# BL702 register map
Vendor: Bouffalo Lab; Series: WiFi BT; File version: 1.0
Registers are 32-bit, read-write, reset 0x0 unless marked. A register's access mark holds for its fields unless they carry their own. Offsets are from the block's base; [hi:lo] are bit positions; {n}, {i} and the like mark numbered series.

## GLB — Global configuration register
Base 0x40000000
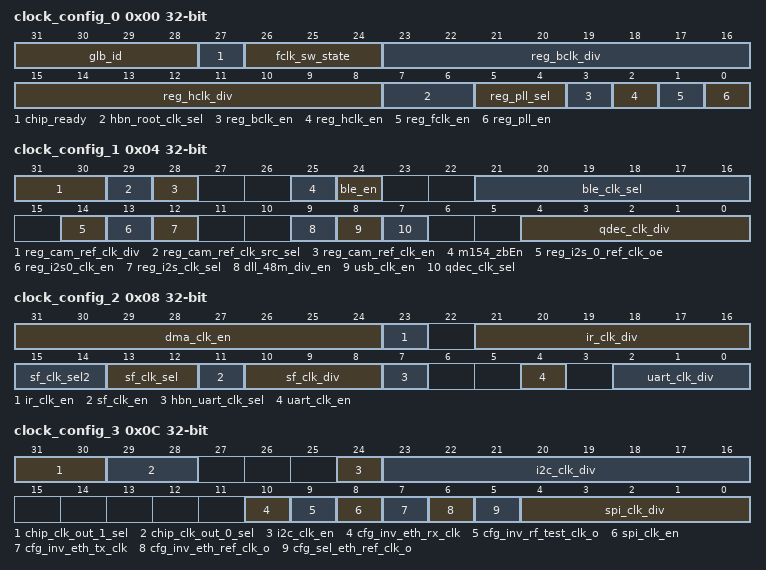
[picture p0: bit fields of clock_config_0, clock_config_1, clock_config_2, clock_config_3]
0x00 clock_config_0 — Clock configuration register 0
  [31:28] glb_id, [27] chip_ready, [26:24] fclk_sw_state, [23:16] reg_bclk_div, [15:8] reg_hclk_div, [7:6] hbn_root_clk_sel, [5:4] reg_pll_sel, [3] reg_bclk_en, [2] reg_hclk_en, [1] reg_fclk_en, [0] reg_pll_en
0x04 clock_config_1 — Clock configuration register 1
  [31:30] reg_cam_ref_clk_div, [29] reg_cam_ref_clk_src_sel, [28] reg_cam_ref_clk_en, [25] m154_zbEn, [24] ble_en, [21:16] ble_clk_sel, [14] reg_i2s_0_ref_clk_oe, [13] reg_i2s0_clk_en, [12] reg_i2s_clk_sel, [9] dll_48m_div_en, [8] usb_clk_en, [7] qdec_clk_sel, [4:0] qdec_clk_div
0x08 clock_config_2 — Clock configuration register 2
  [31:24] dma_clk_en, [23] ir_clk_en, [21:16] ir_clk_div, [15:14] sf_clk_sel2, [13:12] sf_clk_sel, [11] sf_clk_en, [10:8] sf_clk_div, [7] hbn_uart_clk_sel, [4] uart_clk_en, [2:0] uart_clk_div
0x0C clock_config_3 — Clock configuration register 3
  [31:30] chip_clk_out_1_sel, [29:28] chip_clk_out_0_sel, [24] i2c_clk_en, [23:16] i2c_clk_div, [10] cfg_inv_eth_rx_clk, [9] cfg_inv_rf_test_clk_o, [8] spi_clk_en, [7] cfg_inv_eth_tx_clk, [6] cfg_inv_eth_ref_clk_o, [5] cfg_sel_eth_ref_clk_o, [4:0] spi_clk_div
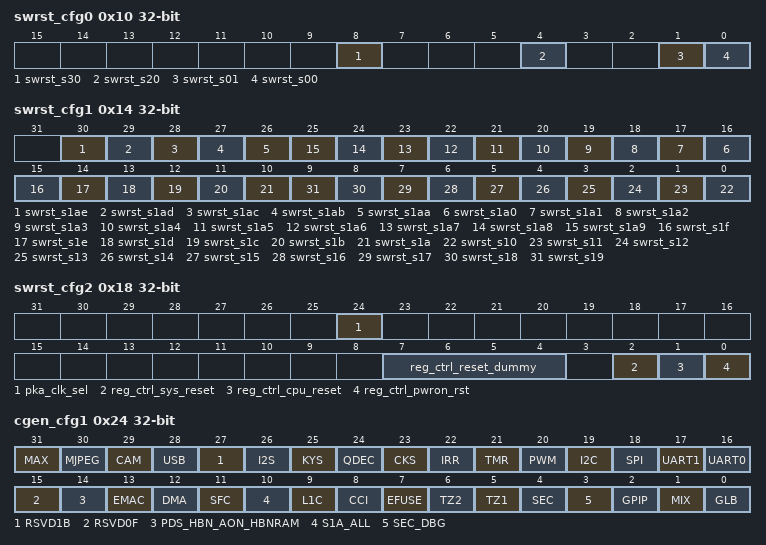
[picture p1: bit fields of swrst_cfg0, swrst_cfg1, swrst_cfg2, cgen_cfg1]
0x10 swrst_cfg0
  [8] swrst_s30, [4] swrst_s20, [1] swrst_s01, [0] swrst_s00
0x14 swrst_cfg1
  [30] swrst_s1ae, [29] swrst_s1ad, [28] swrst_s1ac, [27] swrst_s1ab, [26] swrst_s1aa, [n+16] swrst_s1a{n} (n=0..9), [15] swrst_s1f, [14] swrst_s1e, [13] swrst_s1d, [12] swrst_s1c, [11] swrst_s1b, [10] swrst_s1a, [n-10] swrst_s{n} (n=10..19)
0x18 swrst_cfg2
  [24] pka_clk_sel, [7:4] reg_ctrl_reset_dummy, [2] reg_ctrl_sys_reset, [1] reg_ctrl_cpu_reset, [0] reg_ctrl_pwron_rst
0x1C swrst_cfg3
0x20 cgen_cfg0
  [7:0] cgen_m
0x24 cgen_cfg1
  [31] MAX
  [30] MJPEG
  [29] CAM
  [28] USB — usb clock ungate enable
  [27] RSVD1B
  [26] I2S — i2s and qdec2 clock ungate enable
  [25] KYS
  [24] QDEC — qdec0 clock ungate enable
  [23] CKS — checksum clock ungate enable
  [22] IRR — ir_remote clock ungate enable
  [21] TMR — timer clock ungate enable
  [20] PWM — pwm clock ungate enable
  [19] I2C — i2c clock ungate enable
  [18] SPI — spi clock ungate enable
  [17] UART1 — uart1 clock ungate enable
  [16] UART0 — uart0 clock ungate enable
  [15] RSVD0F
  [14] PDS_HBN_AON_HBNRAM — DS_HBN_AON_HBNRAM
  [13] EMAC — EMAC clock ungate enable
  [12] DMA — DMA clock ungate enable
  [11] SFC — sf_ctrl clock ungate enable
  [10] S1A_ALL — S1A_ALL (efuse?)
  [9] L1C — L1C (efuse?)
  [8] CCI — CCI (efuse?)
  [7] EFUSE — ef_ctrl clock ungate enable
  [6] TZ2 — TZC2 clock ungate enable
  [5] TZ1 — TZC clock ungate enable
  [4] SEC — sec_eng clock ungate enable
  [3] SEC_DBG — sec_dbg clock ungate enable
  [2] GPIP — gpip (gpadc, gpdac) clock ungate enable
  [1] MIX
  [0] GLB
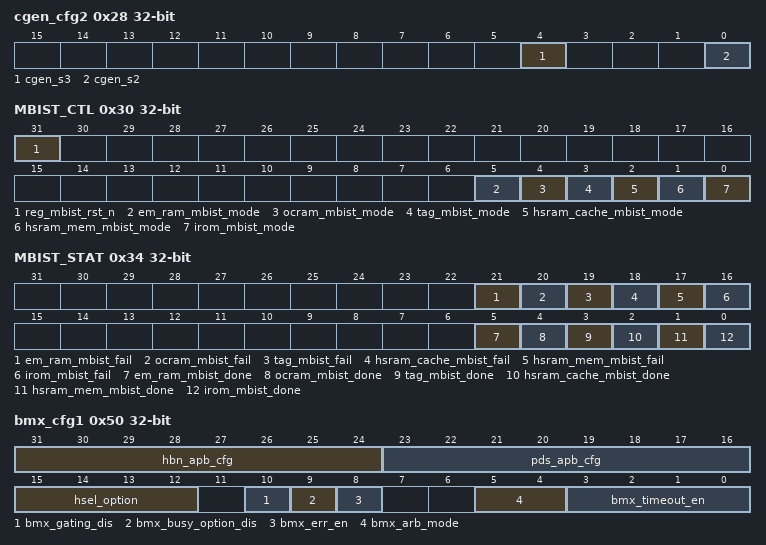
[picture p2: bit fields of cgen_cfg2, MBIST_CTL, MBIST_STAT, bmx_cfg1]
0x28 cgen_cfg2
  [4] cgen_s3, [0] cgen_s2
0x2C cgen_cfg3
0x30 MBIST_CTL
  [31] reg_mbist_rst_n, [5] em_ram_mbist_mode, [4] ocram_mbist_mode, [3] tag_mbist_mode, [2] hsram_cache_mbist_mode, [1] hsram_mem_mbist_mode, [0] irom_mbist_mode
0x34 MBIST_STAT
  [21] em_ram_mbist_fail, [20] ocram_mbist_fail, [19] tag_mbist_fail, [18] hsram_cache_mbist_fail, [17] hsram_mem_mbist_fail, [16] irom_mbist_fail, [5] em_ram_mbist_done, [4] ocram_mbist_done, [3] tag_mbist_done, [2] hsram_cache_mbist_done, [1] hsram_mem_mbist_done, [0] irom_mbist_done
0x50 bmx_cfg1
  [31:24] hbn_apb_cfg, [23:16] pds_apb_cfg, [15:12] hsel_option, [10] bmx_gating_dis, [9] bmx_busy_option_dis, [8] bmx_err_en, [5:4] bmx_arb_mode, [3:0] bmx_timeout_en
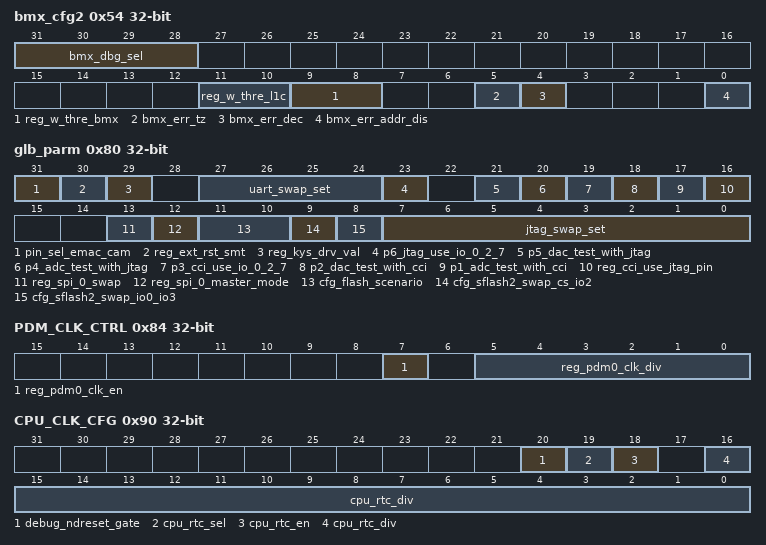
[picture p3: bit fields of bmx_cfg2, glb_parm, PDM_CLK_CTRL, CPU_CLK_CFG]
0x54 bmx_cfg2
  [31:28] bmx_dbg_sel, [11:10] reg_w_thre_l1c, [9:8] reg_w_thre_bmx, [5] bmx_err_tz, [4] bmx_err_dec, [0] bmx_err_addr_dis
0x58 bmx_err_addr
0x5C bmx_dbg_out
{0x60+4i} rsv{i} (i=0..3)
0x70 sram_ret
  [31:0] reg_sram_ret
0x74 sram_slp
  [31:0] reg_sram_slp
0x78 sram_parm
  [31:0] reg_sram_parm
0x7C seam_misc
  [3:0] em_sel
0x80 glb_parm
  [31] pin_sel_emac_cam, [30] reg_ext_rst_smt, [29] reg_kys_drv_val, [27:24] uart_swap_set, [23] p6_jtag_use_io_0_2_7, [21] p5_dac_test_with_jtag, [20] p4_adc_test_with_jtag, [19] p3_cci_use_io_0_2_7, [18] p2_dac_test_with_cci, [17] p1_adc_test_with_cci, [16] reg_cci_use_jtag_pin, [13] reg_spi_0_swap, [12] reg_spi_0_master_mode, [11:10] cfg_flash_scenario, [9] cfg_sflash2_swap_cs_io2, [8] cfg_sflash2_swap_io0_io3, [7:0] jtag_swap_set
0x84 PDM_CLK_CTRL
  [7] reg_pdm0_clk_en, [5:0] reg_pdm0_clk_div
0x88 GPIO_USE_PSRAM__IO
  [5:0] cfg_gpio_use_psram_io
0x90 CPU_CLK_CFG
  [20] debug_ndreset_gate, [19] cpu_rtc_sel, [18] cpu_rtc_en, [16:0] cpu_rtc_div
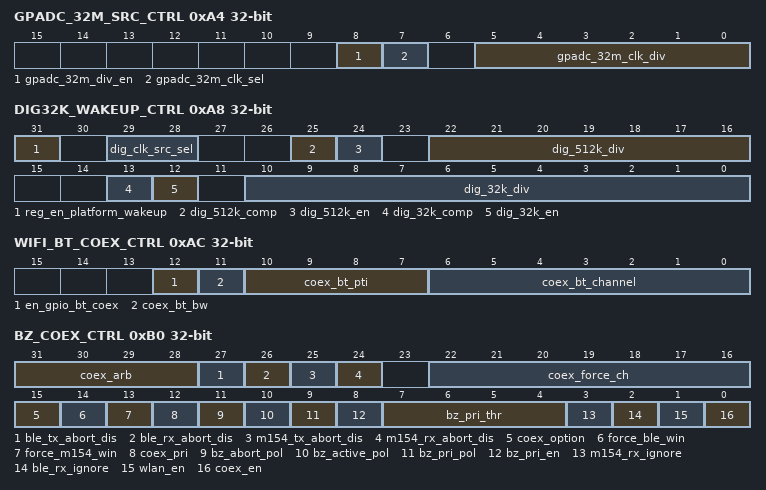
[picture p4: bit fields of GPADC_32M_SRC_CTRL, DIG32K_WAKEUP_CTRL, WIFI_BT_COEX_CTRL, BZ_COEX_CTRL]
0xA4 GPADC_32M_SRC_CTRL
  [8] gpadc_32m_div_en, [7] gpadc_32m_clk_sel, [5:0] gpadc_32m_clk_div
0xA8 DIG32K_WAKEUP_CTRL
  [31] reg_en_platform_wakeup, [29:28] dig_clk_src_sel, [25] dig_512k_comp, [24] dig_512k_en, [22:16] dig_512k_div, [13] dig_32k_comp, [12] dig_32k_en, [10:0] dig_32k_div
0xAC WIFI_BT_COEX_CTRL
  [12] en_gpio_bt_coex, [11] coex_bt_bw, [10:7] coex_bt_pti, [6:0] coex_bt_channel
0xB0 BZ_COEX_CTRL
  [31:28] coex_arb, [27] ble_tx_abort_dis, [26] ble_rx_abort_dis, [25] m154_tx_abort_dis, [24] m154_rx_abort_dis, [22:16] coex_force_ch, [15] coex_option, [14] force_ble_win, [13] force_m154_win, [12] coex_pri, [11] bz_abort_pol, [10] bz_active_pol, [9] bz_pri_pol, [8] bz_pri_en, [7:4] bz_pri_thr, [3] m154_rx_ignore, [2] ble_rx_ignore, [1] wlan_en, [0] coex_en
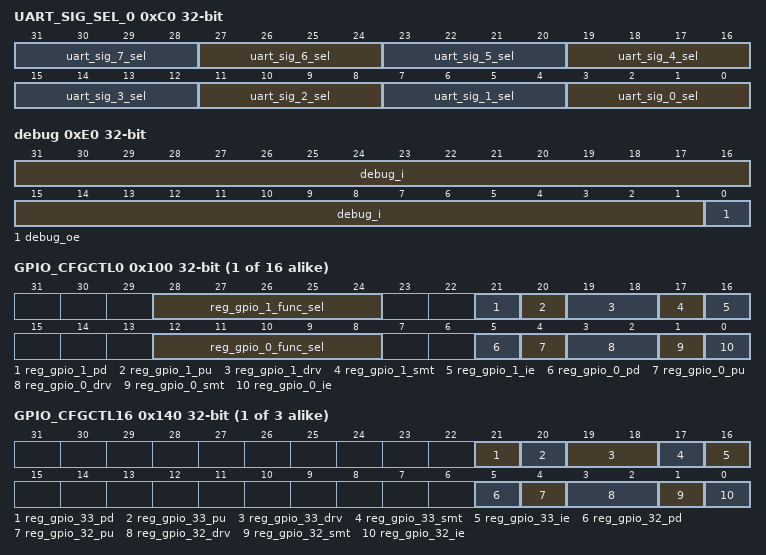
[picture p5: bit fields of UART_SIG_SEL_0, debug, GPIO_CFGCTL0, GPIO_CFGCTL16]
0xC0 UART_SIG_SEL_0
  [4n+3:4n] uart_sig_{n}_sel (n=0..7)
0xD0 DBG_SEL_LL
  [31:0] reg_dbg_ll_ctrl
0xD4 DBG_SEL_LH
  [31:0] reg_dbg_lh_ctrl
0xD8 DBG_SEL_HL
  [31:0] reg_dbg_hl_ctrl
0xDC DBG_SEL_HH
  [31:0] reg_dbg_hh_ctrl
0xE0 debug
  [31:1] debug_i, [0] debug_oe
{0x100+4i} GPIO_CFGCTL{i} (i=0..15)
  [28:24] reg_gpio_{2i+1}_func_sel, [21] reg_gpio_{2i+1}_pd, [20] reg_gpio_{2i+1}_pu, [19:18] reg_gpio_{2i+1}_drv, [17] reg_gpio_{2i+1}_smt, [16] reg_gpio_{2i+1}_ie, [12:8] reg_gpio_{2i}_func_sel, [5] reg_gpio_{2i}_pd, [4] reg_gpio_{2i}_pu, [3:2] reg_gpio_{2i}_drv, [1] reg_gpio_{2i}_smt, [0] reg_gpio_{2i}_ie
{0x100+4i} GPIO_CFGCTL{i} (i=16..18)
  [21] reg_gpio_{2i+1}_pd, [20] reg_gpio_{2i+1}_pu, [19:18] reg_gpio_{2i+1}_drv, [17] reg_gpio_{2i+1}_smt, [16] reg_gpio_{2i+1}_ie, [5] reg_gpio_{2i}_pd, [4] reg_gpio_{2i}_pu, [3:2] reg_gpio_{2i}_drv, [1] reg_gpio_{2i}_smt, [0] reg_gpio_{2i}_ie
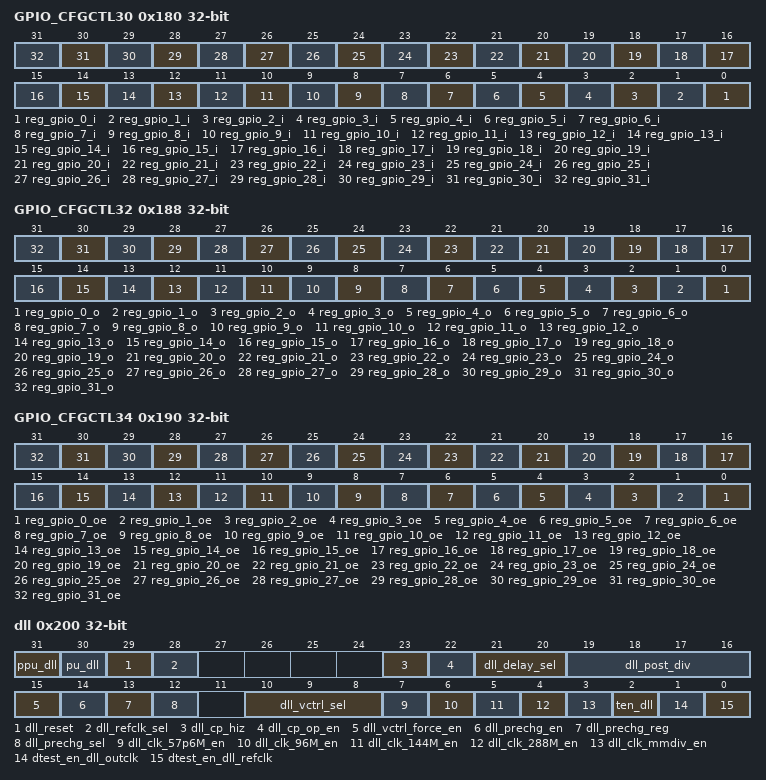
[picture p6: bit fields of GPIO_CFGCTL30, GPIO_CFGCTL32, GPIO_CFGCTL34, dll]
0x180 GPIO_CFGCTL30
  [n] reg_gpio_{n}_i (n=0..31)
0x184 GPIO_CFGCTL31
0x188 GPIO_CFGCTL32
  [n] reg_gpio_{n}_o (n=0..31)
0x18C GPIO_CFGCTL33
0x190 GPIO_CFGCTL34
  [n] reg_gpio_{n}_oe (n=0..31)
0x194 GPIO_CFGCTL35
0x1A0 GPIO_INT_MASK1
  [31:0] reg_gpio_int_mask1
0x1A8 GPIO_INT_STAT1
0x1B0 GPIO_INT_CLR1
  [31:0] reg_gpio_int_clr1
{0x1BC+4i} GPIO_INT_MODE_SET{i} (i=1..3)
  [29:0] reg_gpio_int_mode_set{i}
0x1CC GPIO_INT_MODE_SET4
  [5:0] reg_gpio_int_mode_set4
0x1D0 GPIO_INT2_MASK1
  [31:0] reg_gpio_int2_mask1
0x1D4 GPIO_INT2_STAT1
0x1D8 GPIO_INT2_CLR1
  [31:0] reg_gpio_int2_clr1
{0x1D8+4i} GPIO_INT2_MODE_SET{i} (i=1..3)
  [29:0] reg_gpio_int2_mode_set{i}
0x1E8 GPIO_INT2_MODE_SET4
  [5:0] reg_gpio_int2_mode_set4
0x200 dll
  [31] ppu_dll, [30] pu_dll, [29] dll_reset, [28] dll_refclk_sel, [23] dll_cp_hiz, [22] dll_cp_op_en, [21:20] dll_delay_sel, [19:16] dll_post_div, [15] dll_vctrl_force_en, [14] dll_prechg_en, [13] dll_prechg_reg, [12] dll_prechg_sel, [10:8] dll_vctrl_sel, [7] dll_clk_57p6M_en, [6] dll_clk_96M_en, [5] dll_clk_144M_en, [4] dll_clk_288M_en, [3] dll_clk_mmdiv_en, [2] ten_dll, [1] dtest_en_dll_outclk, [0] dtest_en_dll_refclk
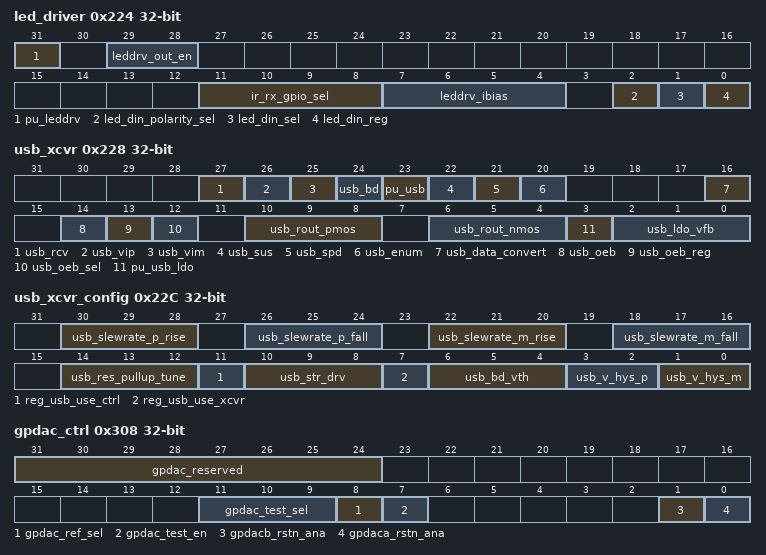
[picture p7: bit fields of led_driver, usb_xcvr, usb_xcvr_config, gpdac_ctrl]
0x224 led_driver
  [31] pu_leddrv, [29:28] leddrv_out_en, [11:8] ir_rx_gpio_sel, [7:4] leddrv_ibias, [2] led_din_polarity_sel, [1] led_din_sel, [0] led_din_reg
0x228 usb_xcvr
  [27] usb_rcv, [26] usb_vip, [25] usb_vim, [24] usb_bd, [23] pu_usb, [22] usb_sus, [21] usb_spd, [20] usb_enum, [16] usb_data_convert, [14] usb_oeb, [13] usb_oeb_reg, [12] usb_oeb_sel, [10:8] usb_rout_pmos, [6:4] usb_rout_nmos, [3] pu_usb_ldo, [2:0] usb_ldo_vfb
0x22C usb_xcvr_config
  [30:28] usb_slewrate_p_rise, [26:24] usb_slewrate_p_fall, [22:20] usb_slewrate_m_rise, [18:16] usb_slewrate_m_fall, [14:12] usb_res_pullup_tune, [11] reg_usb_use_ctrl, [10:8] usb_str_drv, [7] reg_usb_use_xcvr, [6:4] usb_bd_vth, [3:2] usb_v_hys_p, [1:0] usb_v_hys_m
0x308 gpdac_ctrl
  [31:24] gpdac_reserved, [11:9] gpdac_test_sel, [8] gpdac_ref_sel, [7] gpdac_test_en, [1] gpdacb_rstn_ana, [0] gpdaca_rstn_ana
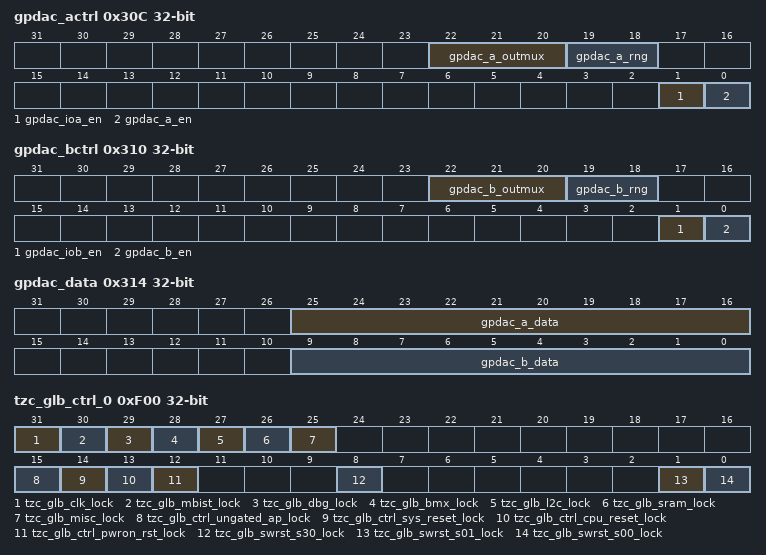
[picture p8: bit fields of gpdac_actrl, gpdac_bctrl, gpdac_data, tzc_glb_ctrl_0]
0x30C gpdac_actrl
  [22:20] gpdac_a_outmux, [19:18] gpdac_a_rng, [1] gpdac_ioa_en, [0] gpdac_a_en
0x310 gpdac_bctrl
  [22:20] gpdac_b_outmux, [19:18] gpdac_b_rng, [1] gpdac_iob_en, [0] gpdac_b_en
0x314 gpdac_data
  [25:16] gpdac_a_data, [9:0] gpdac_b_data
0xE00 chip_revision
  [3:0] chip_rev
0xF00 tzc_glb_ctrl_0
  [31] tzc_glb_clk_lock, [30] tzc_glb_mbist_lock, [29] tzc_glb_dbg_lock, [28] tzc_glb_bmx_lock, [27] tzc_glb_l2c_lock, [26] tzc_glb_sram_lock, [25] tzc_glb_misc_lock, [15] tzc_glb_ctrl_ungated_ap_lock, [14] tzc_glb_ctrl_sys_reset_lock, [13] tzc_glb_ctrl_cpu_reset_lock, [12] tzc_glb_ctrl_pwron_rst_lock, [8] tzc_glb_swrst_s30_lock, [1] tzc_glb_swrst_s01_lock, [0] tzc_glb_swrst_s00_lock
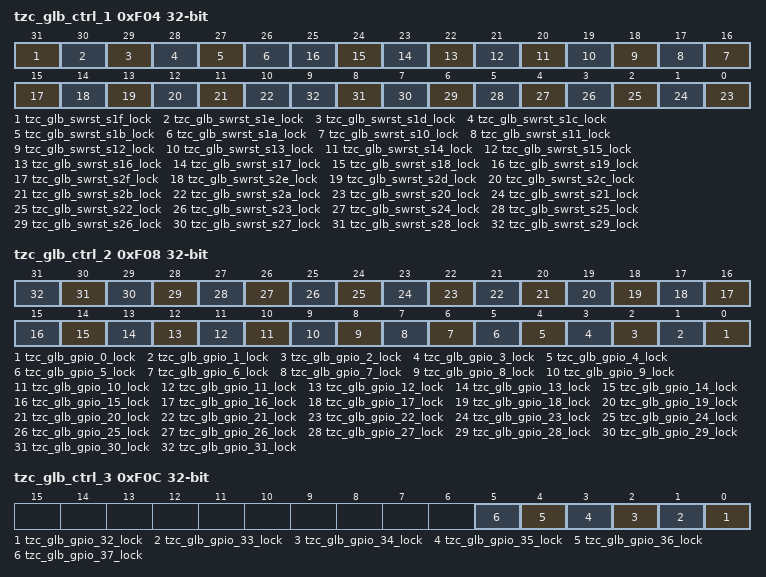
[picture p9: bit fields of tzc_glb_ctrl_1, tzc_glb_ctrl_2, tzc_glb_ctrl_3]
0xF04 tzc_glb_ctrl_1
  [31] tzc_glb_swrst_s1f_lock, [30] tzc_glb_swrst_s1e_lock, [29] tzc_glb_swrst_s1d_lock, [28] tzc_glb_swrst_s1c_lock, [27] tzc_glb_swrst_s1b_lock, [26] tzc_glb_swrst_s1a_lock, [n+6] tzc_glb_swrst_s{n}_lock (n=10..19), [15] tzc_glb_swrst_s2f_lock, [14] tzc_glb_swrst_s2e_lock, [13] tzc_glb_swrst_s2d_lock, [12] tzc_glb_swrst_s2c_lock, [11] tzc_glb_swrst_s2b_lock, [10] tzc_glb_swrst_s2a_lock, [n-20] tzc_glb_swrst_s{n}_lock (n=20..29)
0xF08 tzc_glb_ctrl_2
  [n] tzc_glb_gpio_{n}_lock (n=0..31)
0xF0C tzc_glb_ctrl_3
  [n-32] tzc_glb_gpio_{n}_lock (n=32..37)
